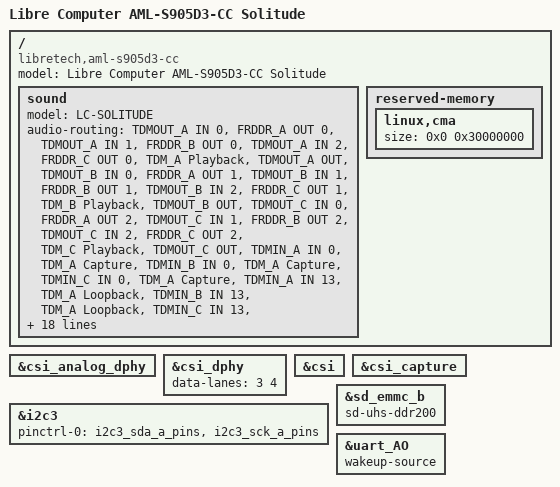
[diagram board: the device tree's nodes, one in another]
// SPDX-License-Identifier: (GPL-2.0+ OR MIT)
/*
 * Copyright (c) 2023 BayLibre, SAS.
 * Author: Jerome Brunet <jbrunet@baylibre.com>
 *
 * AML-S905D3-CC board body, shared by the two firmware layouts this board
 * boots: meson-sm1-s905d3-libretech-cc.dts (vendor chain) and
 * meson-sm1-s905d3-libretech-cc-libre.dts (libre chain). The firmware
 * reservations are the leaf's, never this file's.
 */

#include <dt-bindings/clock/g12a-clkc.h>
#include "meson-sm1.dtsi"
#include "meson-libretech-cottonwood.dtsi"

/ {
	compatible = "libretech,aml-s905d3-cc", "amlogic,sm1";
	model = "Libre Computer AML-S905D3-CC Solitude";

	sound {
		model = "LC-SOLITUDE";
		audio-routing = "TDMOUT_A IN 0", "FRDDR_A OUT 0",
				"TDMOUT_A IN 1", "FRDDR_B OUT 0",
				"TDMOUT_A IN 2", "FRDDR_C OUT 0",
				"TDM_A Playback", "TDMOUT_A OUT",
				"TDMOUT_B IN 0", "FRDDR_A OUT 1",
				"TDMOUT_B IN 1", "FRDDR_B OUT 1",
				"TDMOUT_B IN 2", "FRDDR_C OUT 1",
				"TDM_B Playback", "TDMOUT_B OUT",
				"TDMOUT_C IN 0", "FRDDR_A OUT 2",
				"TDMOUT_C IN 1", "FRDDR_B OUT 2",
				"TDMOUT_C IN 2", "FRDDR_C OUT 2",
				"TDM_C Playback", "TDMOUT_C OUT",
				"TDMIN_A IN 0", "TDM_A Capture",
				"TDMIN_B IN 0", "TDM_A Capture",
				"TDMIN_C IN 0", "TDM_A Capture",
				"TDMIN_A IN 13", "TDM_A Loopback",
				"TDMIN_B IN 13", "TDM_A Loopback",
				"TDMIN_C IN 13", "TDM_A Loopback",
				"TDMIN_A IN 1", "TDM_B Capture",
				"TDMIN_B IN 1", "TDM_B Capture",
				"TDMIN_C IN 1", "TDM_B Capture",
				"TDMIN_A IN 14", "TDM_B Loopback",
				"TDMIN_B IN 14", "TDM_B Loopback",
				"TDMIN_C IN 14", "TDM_B Loopback",
				"TDMIN_A IN 2", "TDM_C Capture",
				"TDMIN_B IN 2", "TDM_C Capture",
				"TDMIN_C IN 2", "TDM_C Capture",
				"TDMIN_A IN 15", "TDM_C Loopback",
				"TDMIN_B IN 15", "TDM_C Loopback",
				"TDMIN_C IN 15", "TDM_C Loopback",
				"TODDR_A IN 0", "TDMIN_A OUT",
				"TODDR_B IN 0", "TDMIN_A OUT",
				"TODDR_C IN 0", "TDMIN_A OUT",
				"TODDR_A IN 1", "TDMIN_B OUT",
				"TODDR_B IN 1", "TDMIN_B OUT",
				"TODDR_C IN 1", "TDMIN_B OUT",
				"TODDR_A IN 2", "TDMIN_C OUT",
				"TODDR_B IN 2", "TDMIN_C OUT",
				"TODDR_C IN 2", "TDMIN_C OUT",
				"Lineout", "ACODEC LOLP",
				"Lineout", "ACODEC LORP";
	};
};

&csi_analog_dphy {
	status = "okay";
};

&csi_dphy {
	status = "okay";
	/*
	 * Physical lane mapping for this board's J21 CSI connector.
	 * Lanes 3,4 (1-indexed) connect to the GPIOAO_10 connector.
	 */
	data-lanes = <3 4>;
};

&csi {
	status = "okay";
};

&csi_capture {
	status = "okay";
};

&i2c3 {
	status = "okay";
	pinctrl-0 = <&i2c3_sda_a_pins>, <&i2c3_sck_a_pins>;
	pinctrl-names = "default";
};


&sd_emmc_b {
	/*
	 * Opt this board's SD card slot into SD UHS DDR200 / DDR208 (200 MHz
	 * DDR) via the generic sd-uhs-ddr200 host opt-in. DDR200 reuses the
	 * SDR104 (1.8 V) signalling already enabled in
	 * meson-libretech-cottonwood.dtsi and only engages for a card that
	 * advertises it and accepts the group-2 function-14 activation; the
	 * core falls back to SDR104 if tuning fails. Board-scoped because it
	 * needs a 400 MHz module clock and clean slot signal integrity.
	 */
	sd-uhs-ddr200;
};

&uart_AO {
	/*
	 * The console UART wakes the board: a keypress on the console ends
	 * suspend-to-idle with no userspace setup. Board-scoped: the AO UART is
	 * enabled in meson-libretech-cottonwood.dtsi, which AML-A311D-CC shares.
	 */
	wakeup-source;
};

/ {
	reserved-memory {
		linux,cma {
			/*
			 * AML-S905D3-CC comes in up to 4 GiB RAM variants.
			 * U-Boot's meson_fixup_cma_size() writes min(this
			 * value, 7/32 of detected RAM) here and forces
			 * alloc-ranges to the first 1 GiB, so this value is the
			 * binding clamp whenever it is the smaller term.
			 *
			 * 768 MiB, not the 896 MiB the 7/32 formula yields at
			 * 4 GiB: the sub-1 GiB window is not 1 GiB wide.
			 * secmon, ramoops and the kernel image leave ~820 MiB
			 * of largest free run below 0x40000000, and 896 MiB was
			 * measured failing on both A311D and S905D3. A failed
			 * reservation costs the whole pool -- one pr_err, then
			 * CONFIG_CMA_SIZE_MBYTES=128 -- so over-asking loses
			 * 640 MiB rather than gaining 128.
			 */
			size = <0x0 0x30000000>;
		};
	};
};
